VERSION ""

NS_ :

BS_:

BU_: Tester RearECU MyECU

BO_ 3221225472 VECTOR__INDEPENDENT_SIG_MSG: 0 Vector__XXX
 SG_ sig_nm_RearECU : 0|64@1+ (1,0) [0|1.8446744074E+019] "" Vector__XXX
 SG_ sig_nm_MyECU : 0|64@1+ (1,0) [0|1.8446744074E+019] "" Vector__XXX

BO_ 1297 msg_MyECU_Lamp: 8 MyECU
 SG_ sig_LampCnt : 7|8@0+ (1,0) [0|255] ""  RearECU

BO_ 512 msg_Transmit: 1 MyECU
 SG_ sig_RearInteriorLight : 0|1@1+ (1,0) [0|1] ""  RearECU

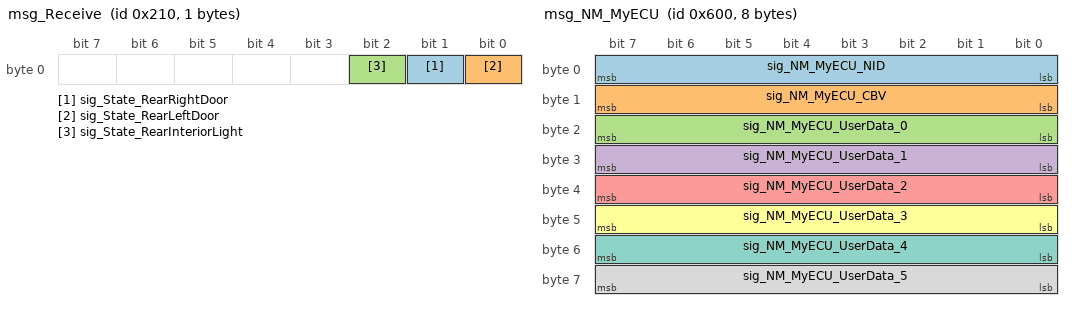
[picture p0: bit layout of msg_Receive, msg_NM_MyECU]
BO_ 528 msg_Receive: 1 RearECU
 SG_ sig_State_RearRightDoor : 1|1@1+ (1,0) [0|1] ""  MyECU
 SG_ sig_State_RearLeftDoor : 0|1@1+ (1,0) [0|1] ""  MyECU
 SG_ sig_State_RearInteriorLight : 2|1@1+ (1,0) [0|1] ""  MyECU

BO_ 1536 msg_NM_MyECU: 8 MyECU
 SG_ sig_NM_MyECU_NID : 0|8@1+ (1,0) [0|255] ""  RearECU
 SG_ sig_NM_MyECU_CBV : 8|8@1+ (1,0) [0|255] ""  RearECU
 SG_ sig_NM_MyECU_UserData_0 : 16|8@1+ (1,0) [0|255] ""  RearECU
 SG_ sig_NM_MyECU_UserData_1 : 24|8@1+ (1,0) [0|255] ""  RearECU
 SG_ sig_NM_MyECU_UserData_2 : 32|8@1+ (1,0) [0|255] ""  RearECU
 SG_ sig_NM_MyECU_UserData_3 : 40|8@1+ (1,0) [0|255] ""  RearECU
 SG_ sig_NM_MyECU_UserData_4 : 48|8@1+ (1,0) [0|255] ""  RearECU
 SG_ sig_NM_MyECU_UserData_5 : 56|8@1+ (1,0) [0|255] ""  RearECU

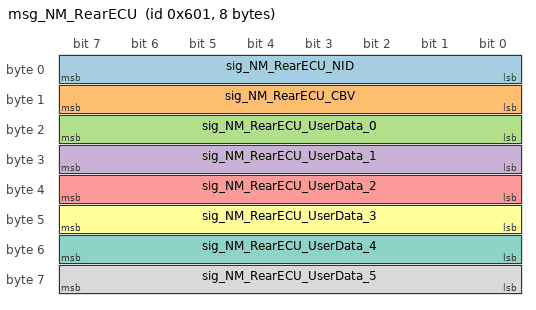
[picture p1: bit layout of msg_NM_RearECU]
BO_ 1537 msg_NM_RearECU: 8 RearECU
 SG_ sig_NM_RearECU_NID : 0|8@1+ (1,0) [0|255] ""  MyECU
 SG_ sig_NM_RearECU_CBV : 8|8@1+ (1,0) [0|255] ""  MyECU
 SG_ sig_NM_RearECU_UserData_0 : 16|8@1+ (1,0) [0|255] ""  MyECU
 SG_ sig_NM_RearECU_UserData_1 : 24|8@1+ (1,0) [0|255] ""  MyECU
 SG_ sig_NM_RearECU_UserData_2 : 32|8@1+ (1,0) [0|255] ""  MyECU
 SG_ sig_NM_RearECU_UserData_3 : 40|8@1+ (1,0) [0|255] ""  MyECU
 SG_ sig_NM_RearECU_UserData_4 : 48|8@1+ (1,0) [0|255] ""  MyECU
 SG_ sig_NM_RearECU_UserData_5 : 56|8@1+ (1,0) [0|255] ""  MyECU

CM_ BO_ 3221225472 "This is a message for not used signals, created by Vector CANdb++ DBC OLE DB Provider.";
BA_DEF_ BO_  "VFrameFormat" ENUM  "StandardCAN","ExtendedCAN","reserved","reserved","reserved","reserved","reserved","reserved","reserved","reserved","reserved","reserved","reserved","reserved","StandardCAN_FD","ExtendedCAN_FD";
BA_DEF_ BO_  "GenMsgCycleTime" INT 0 0;
BA_DEF_ BO_  "GenMsgSendType" ENUM  "cyclicX","spontanX","cyclicIfActiveX","spontanWithDelay","cyclicAndSpontanX","cyclicAndSpontanWithDelay","spontanWithRepetition","cyclicIfActiveAndSpontanWD","cyclicIfActiveFast","cyclicWithRepeatOnDemand";
BA_DEF_ SG_  "GenSigCycleTimeActive" INT 0 0;
BA_DEF_ SG_  "GenSigCycleTime" INT 0 0;
BA_DEF_ SG_  "GenSigSendType" ENUM  "cyclicX","spontanX","cyclicIfActiveX","spontanWithDelay","cyclicAndSpontanX","cyclicAndSpontanWithDelay","spontanWithRepetition","cyclicIfActiveAndSpontanWD","cyclicIfActiveFast","cyclicWithRepeatOnDemand","none","NotUsed","NotUsed";
BA_DEF_  "Baudrate" INT 0 1000000;
BA_DEF_  "BusType" STRING ;
BA_DEF_  "Manufacturer" STRING ;
BA_DEF_ BU_  "ILUsed" ENUM  "no","yes";
BA_DEF_ BO_  "GenMsgILSupport" ENUM  "no","yes";
BA_DEF_ BO_  "NmMessage" ENUM  "no","yes";
BA_DEF_ SG_  "NmSignalRole" ENUM  "Other","NID","CBV","UserData";
BA_DEF_  "NmAsrBaseAddress" HEX 0 1791;
BA_DEF_ BU_  "NmAsrCanMsgCycleOffset" INT 0 65535;
BA_DEF_  "NmAsrMsgCycleTime" INT 0 65535;
BA_DEF_ BU_  "NmAsrMsgReducedTime" INT 0 65535;
BA_DEF_ BO_  "NmAsrMessage" ENUM  "no","yes";
BA_DEF_  "NmAsrMessageCount" INT 0 256;
BA_DEF_ BU_  "NmAsrNode" ENUM  "no","yes";
BA_DEF_ BU_  "NmAsrNodeIdentifier" INT 0 255;
BA_DEF_  "NmType" STRING ;
BA_DEF_DEF_  "VFrameFormat" "ExtendedCAN_FD";
BA_DEF_DEF_  "GenMsgCycleTime" 0;
BA_DEF_DEF_  "GenMsgSendType" "cyclicX";
BA_DEF_DEF_  "GenSigCycleTimeActive" 0;
BA_DEF_DEF_  "GenSigCycleTime" 0;
BA_DEF_DEF_  "GenSigSendType" "cyclicX";
BA_DEF_DEF_  "Baudrate" 500000;
BA_DEF_DEF_  "BusType" "";
BA_DEF_DEF_  "Manufacturer" "Vector";
BA_DEF_DEF_  "ILUsed" "yes";
BA_DEF_DEF_  "GenMsgILSupport" "yes";
BA_DEF_DEF_  "NmMessage" "no";
BA_DEF_DEF_  "NmSignalRole" "Other";
BA_DEF_DEF_  "NmAsrBaseAddress" 1536;
BA_DEF_DEF_  "NmAsrCanMsgCycleOffset" 0;
BA_DEF_DEF_  "NmAsrMsgCycleTime" 100;
BA_DEF_DEF_  "NmAsrMsgReducedTime" 50;
BA_DEF_DEF_  "NmAsrMessage" "no";
BA_DEF_DEF_  "NmAsrMessageCount" 64;
BA_DEF_DEF_  "NmAsrNode" "yes";
BA_DEF_DEF_  "NmAsrNodeIdentifier" 0;
BA_DEF_DEF_  "NmType" "Asr";
BA_ "Baudrate" 0;
BA_ "BusType" "CAN FD";
BA_ "NmAsrNode" BU_ Tester 0;
BA_ "NmAsrNodeIdentifier" BU_ RearECU 1;
BA_ "GenMsgCycleTime" BO_ 1297 100;
BA_ "VFrameFormat" BO_ 1297 0;
BA_ "GenMsgCycleTime" BO_ 512 100;
BA_ "VFrameFormat" BO_ 512 0;
BA_ "GenMsgCycleTime" BO_ 528 100;
BA_ "VFrameFormat" BO_ 528 0;
BA_ "NmMessage" BO_ 1536 1;
BA_ "NmAsrMessage" BO_ 1536 1;
BA_ "GenMsgCycleTime" BO_ 1536 100;
BA_ "VFrameFormat" BO_ 1536 0;
BA_ "NmMessage" BO_ 1537 1;
BA_ "NmAsrMessage" BO_ 1537 1;
BA_ "GenMsgCycleTime" BO_ 1537 100;
BA_ "VFrameFormat" BO_ 1537 0;
BA_ "GenSigCycleTimeActive" SG_ 3221225472 sig_nm_RearECU 100;
BA_ "GenSigCycleTime" SG_ 3221225472 sig_nm_RearECU 100;
BA_ "GenSigCycleTimeActive" SG_ 3221225472 sig_nm_MyECU 100;
BA_ "GenSigCycleTime" SG_ 3221225472 sig_nm_MyECU 100;
BA_ "GenSigCycleTimeActive" SG_ 512 sig_RearInteriorLight 100;
BA_ "GenSigCycleTime" SG_ 512 sig_RearInteriorLight 100;
BA_ "GenSigCycleTimeActive" SG_ 528 sig_State_RearRightDoor 100;
BA_ "GenSigCycleTime" SG_ 528 sig_State_RearRightDoor 100;
BA_ "GenSigCycleTimeActive" SG_ 528 sig_State_RearLeftDoor 100;
BA_ "GenSigCycleTime" SG_ 528 sig_State_RearLeftDoor 100;
BA_ "GenSigCycleTimeActive" SG_ 528 sig_State_RearInteriorLight 100;
BA_ "GenSigCycleTime" SG_ 528 sig_State_RearInteriorLight 100;
BA_ "NmSignalRole" SG_ 1536 sig_NM_MyECU_NID 1;
BA_ "GenSigCycleTimeActive" SG_ 1536 sig_NM_MyECU_NID 100;
BA_ "GenSigCycleTime" SG_ 1536 sig_NM_MyECU_NID 100;
BA_ "NmSignalRole" SG_ 1536 sig_NM_MyECU_CBV 2;
BA_ "GenSigCycleTimeActive" SG_ 1536 sig_NM_MyECU_CBV 100;
BA_ "GenSigCycleTime" SG_ 1536 sig_NM_MyECU_CBV 100;
BA_ "NmSignalRole" SG_ 1536 sig_NM_MyECU_UserData_0 3;
BA_ "GenSigCycleTimeActive" SG_ 1536 sig_NM_MyECU_UserData_0 100;
BA_ "GenSigCycleTime" SG_ 1536 sig_NM_MyECU_UserData_0 100;
BA_ "NmSignalRole" SG_ 1536 sig_NM_MyECU_UserData_1 3;
BA_ "GenSigCycleTimeActive" SG_ 1536 sig_NM_MyECU_UserData_1 100;
BA_ "GenSigCycleTime" SG_ 1536 sig_NM_MyECU_UserData_1 100;
BA_ "NmSignalRole" SG_ 1536 sig_NM_MyECU_UserData_2 3;
BA_ "GenSigCycleTimeActive" SG_ 1536 sig_NM_MyECU_UserData_2 100;
BA_ "GenSigCycleTime" SG_ 1536 sig_NM_MyECU_UserData_2 100;
BA_ "NmSignalRole" SG_ 1536 sig_NM_MyECU_UserData_3 3;
BA_ "GenSigCycleTimeActive" SG_ 1536 sig_NM_MyECU_UserData_3 100;
BA_ "GenSigCycleTime" SG_ 1536 sig_NM_MyECU_UserData_3 100;
BA_ "NmSignalRole" SG_ 1536 sig_NM_MyECU_UserData_4 3;
BA_ "GenSigCycleTimeActive" SG_ 1536 sig_NM_MyECU_UserData_4 100;
BA_ "GenSigCycleTime" SG_ 1536 sig_NM_MyECU_UserData_4 100;
BA_ "NmSignalRole" SG_ 1536 sig_NM_MyECU_UserData_5 3;
BA_ "GenSigCycleTimeActive" SG_ 1536 sig_NM_MyECU_UserData_5 100;
BA_ "GenSigCycleTime" SG_ 1536 sig_NM_MyECU_UserData_5 100;
BA_ "NmSignalRole" SG_ 1537 sig_NM_RearECU_NID 1;
BA_ "GenSigCycleTimeActive" SG_ 1537 sig_NM_RearECU_NID 100;
BA_ "GenSigCycleTime" SG_ 1537 sig_NM_RearECU_NID 100;
BA_ "NmSignalRole" SG_ 1537 sig_NM_RearECU_CBV 2;
BA_ "GenSigCycleTimeActive" SG_ 1537 sig_NM_RearECU_CBV 100;
BA_ "GenSigCycleTime" SG_ 1537 sig_NM_RearECU_CBV 100;
BA_ "NmSignalRole" SG_ 1537 sig_NM_RearECU_UserData_0 3;
BA_ "GenSigCycleTimeActive" SG_ 1537 sig_NM_RearECU_UserData_0 100;
BA_ "GenSigCycleTime" SG_ 1537 sig_NM_RearECU_UserData_0 100;
BA_ "NmSignalRole" SG_ 1537 sig_NM_RearECU_UserData_1 3;
BA_ "GenSigCycleTimeActive" SG_ 1537 sig_NM_RearECU_UserData_1 100;
BA_ "GenSigCycleTime" SG_ 1537 sig_NM_RearECU_UserData_1 100;
BA_ "NmSignalRole" SG_ 1537 sig_NM_RearECU_UserData_2 3;
BA_ "GenSigCycleTimeActive" SG_ 1537 sig_NM_RearECU_UserData_2 100;
BA_ "GenSigCycleTime" SG_ 1537 sig_NM_RearECU_UserData_2 100;
BA_ "NmSignalRole" SG_ 1537 sig_NM_RearECU_UserData_3 3;
BA_ "GenSigCycleTimeActive" SG_ 1537 sig_NM_RearECU_UserData_3 100;
BA_ "GenSigCycleTime" SG_ 1537 sig_NM_RearECU_UserData_3 100;
BA_ "NmSignalRole" SG_ 1537 sig_NM_RearECU_UserData_4 3;
BA_ "GenSigCycleTimeActive" SG_ 1537 sig_NM_RearECU_UserData_4 100;
BA_ "GenSigCycleTime" SG_ 1537 sig_NM_RearECU_UserData_4 100;
BA_ "NmSignalRole" SG_ 1537 sig_NM_RearECU_UserData_5 3;
BA_ "GenSigCycleTimeActive" SG_ 1537 sig_NM_RearECU_UserData_5 100;
BA_ "GenSigCycleTime" SG_ 1537 sig_NM_RearECU_UserData_5 100;
